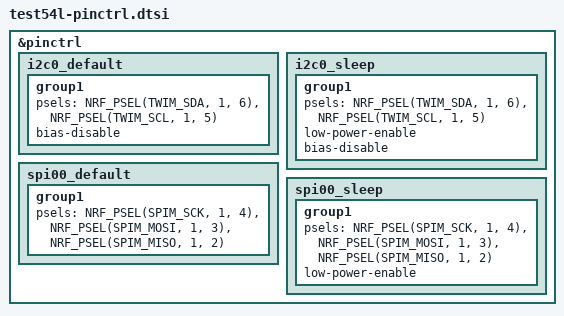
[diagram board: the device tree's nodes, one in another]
&pinctrl {
	i2c0_default: i2c0_default {
		group1 {
			psels = <NRF_PSEL(TWIM_SDA, 1, 6)>,
				<NRF_PSEL(TWIM_SCL, 1, 5)>;
			bias-disable;
		};
	};

	i2c0_sleep: i2c0_sleep {
		group1 {
			psels = <NRF_PSEL(TWIM_SDA, 1, 6)>,
				<NRF_PSEL(TWIM_SCL, 1, 5)>;
			low-power-enable;
			bias-disable;
		};
	};

	spi00_default: spi00_default {
		group1 {
			psels = <NRF_PSEL(SPIM_SCK, 1, 4)>,
				<NRF_PSEL(SPIM_MOSI, 1, 3)>,
				<NRF_PSEL(SPIM_MISO, 1, 2)>;
		};
	};

	spi00_sleep: spi00_sleep {
		group1 {
			psels = <NRF_PSEL(SPIM_SCK, 1, 4)>,
				<NRF_PSEL(SPIM_MOSI, 1, 3)>,
				<NRF_PSEL(SPIM_MISO, 1, 2)>;
				low-power-enable;
		};
	};

};
